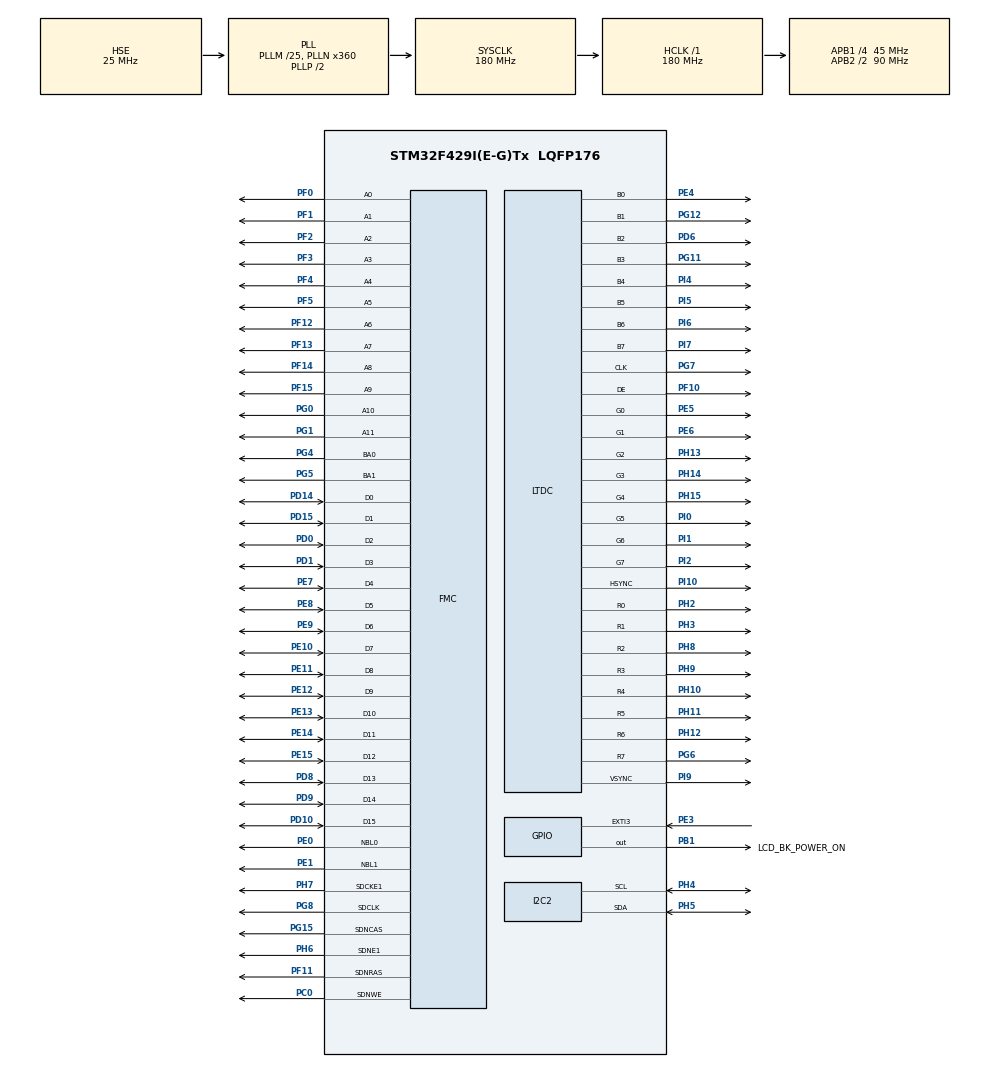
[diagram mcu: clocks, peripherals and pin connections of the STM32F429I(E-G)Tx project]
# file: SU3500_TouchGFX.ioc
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FMC.CASLatency1=FMC_SDRAM_CAS_LATENCY_3
FMC.ExitSelfRefreshDelay1=7
FMC.LoadToActiveDelay1=2
FMC.RCDDelay1=2
FMC.RPDelay1=2
FMC.ReadPipeDelay1=FMC_SDRAM_RPIPE_DELAY_1
FMC.RowCycleDelay1=6
FMC.SDClockPeriod1=FMC_SDRAM_CLOCK_PERIOD_2
FMC.SelfRefreshTime1=4
FMC.WriteRecoveryTime1=3
LTDC.ActiveW=800
LTDC.Alpha_L0=255
LTDC.DEPolarity=LTDC_DEPOLARITY_AL
LTDC.FBStartAdress_L0=0xD0000000
LTDC.HBP=88
LTDC.HFP=40
LTDC.HSync=48
LTDC.ImageHeight_L0=480
LTDC.ImageWidth_L0=800
LTDC.Layers=0
LTDC.PixelFormat_L0=LTDC_PIXEL_FORMAT_RGB888
LTDC.VBP=32
LTDC.VFP=13
LTDC.VSync=3
LTDC.WindowX1_L0=800
LTDC.WindowY1_L0=480
Mcu.Family=STM32F4
Mcu.Name=STM32F429I(E-G)Tx
Mcu.Package=LQFP176
NVIC.EXTI3_IRQn=true\:0\:0\:false\:false\:true\:true\:true\:true
NVIC.I2C2_ER_IRQn=true\:0\:0\:false\:false\:true\:true\:true\:true
NVIC.I2C2_EV_IRQn=true\:0\:0\:false\:false\:true\:true\:true\:true
NVIC.LTDC_IRQn=true\:0\:0\:false\:false\:true\:true\:true\:true
NVIC.PriorityGroup=NVIC_PRIORITYGROUP_4
PA13.Mode=Serial_Wire
PA13.Signal=SYS_JTMS-SWDIO
PA14.Mode=Serial_Wire
PA14.Signal=SYS_JTCK-SWCLK
PB1.GPIO_Label=LCD_BK_POWER_ON
PB1.PinState=GPIO_PIN_SET
PB1.Signal=GPIO_Output
PC0.Signal=FMC_SDNWE
PD0.Signal=FMC_D2_DA2
PD1.Signal=FMC_D3_DA3
PD10.Signal=FMC_D15_DA15
PD14.Signal=FMC_D0_DA0
PD15.Signal=FMC_D1_DA1
PD6.Mode=RGB888
PD6.Signal=LTDC_B2
PD8.Signal=FMC_D13_DA13
PD9.Signal=FMC_D14_DA14
PE0.Signal=FMC_NBL0
PE1.Signal=FMC_NBL1
PE10.Signal=FMC_D7_DA7
PE11.Signal=FMC_D8_DA8
PE12.Signal=FMC_D9_DA9
PE13.Signal=FMC_D10_DA10
PE14.Signal=FMC_D11_DA11
PE15.Signal=FMC_D12_DA12
PE3.GPIO_ModeDefaultEXTI=GPIO_MODE_IT_FALLING
PE3.GPIO_PuPd=GPIO_PULLUP
PE3.Signal=GPXTI3
PE4.GPIO_Speed=GPIO_SPEED_FREQ_VERY_HIGH
PE4.Mode=RGB888
PE4.Signal=LTDC_B0
PE5.Mode=RGB888
PE5.Signal=LTDC_G0
PE6.Mode=RGB888
PE6.Signal=LTDC_G1
PE7.Signal=FMC_D4_DA4
PE8.Signal=FMC_D5_DA5
PE9.Signal=FMC_D6_DA6
PF0.Signal=FMC_A0
PF1.Signal=FMC_A1
PF10.GPIO_Speed=GPIO_SPEED_FREQ_VERY_HIGH
PF10.Mode=RGB888
PF10.Signal=LTDC_DE
PF11.Signal=FMC_SDNRAS
PF12.Signal=FMC_A6
PF13.Signal=FMC_A7
PF14.Signal=FMC_A8
PF15.Signal=FMC_A9
PF2.Signal=FMC_A2
PF3.Signal=FMC_A3
PF4.Signal=FMC_A4
PF5.Signal=FMC_A5
PG0.Signal=FMC_A10
PG1.Signal=FMC_A11
PG11.GPIO_Speed=GPIO_SPEED_FREQ_VERY_HIGH
PG11.Mode=RGB888
PG11.Signal=LTDC_B3
PG12.Mode=RGB888
PG12.Signal=LTDC_B1
PG15.Signal=FMC_SDNCAS
PG4.Signal=FMC_A14_BA0
PG5.Signal=FMC_A15_BA1
PG6.GPIO_Speed=GPIO_SPEED_FREQ_VERY_HIGH
PG6.Mode=RGB888
PG6.Signal=LTDC_R7
PG7.GPIO_Speed=GPIO_SPEED_FREQ_VERY_HIGH
PG7.Mode=RGB888
PG7.Signal=LTDC_CLK
PG8.Signal=FMC_SDCLK
PH0/OSC_IN.Mode=HSE-External-Oscillator
PH0/OSC_IN.Signal=RCC_OSC_IN
PH1/OSC_OUT.Mode=HSE-External-Oscillator
PH1/OSC_OUT.Signal=RCC_OSC_OUT
PH10.GPIO_Speed=GPIO_SPEED_FREQ_VERY_HIGH
PH10.Mode=RGB888
PH10.Signal=LTDC_R4
PH11.GPIO_Speed=GPIO_SPEED_FREQ_VERY_HIGH
PH11.Mode=RGB888
PH11.Signal=LTDC_R5
PH12.GPIO_Speed=GPIO_SPEED_FREQ_VERY_HIGH
PH12.Mode=RGB888
PH12.Signal=LTDC_R6
PH13.GPIO_Speed=GPIO_SPEED_FREQ_VERY_HIGH
PH13.Mode=RGB888
PH13.Signal=LTDC_G2
PH14.GPIO_Speed=GPIO_SPEED_FREQ_VERY_HIGH
PH14.Mode=RGB888
PH14.Signal=LTDC_G3
PH15.GPIO_Speed=GPIO_SPEED_FREQ_VERY_HIGH
PH15.Mode=RGB888
PH15.Signal=LTDC_G4
PH2.Mode=RGB888
PH2.Signal=LTDC_R0
PH3.Mode=RGB888
PH3.Signal=LTDC_R1
PH4.Mode=I2C
PH4.Signal=I2C2_SCL
PH5.Mode=I2C
PH5.Signal=I2C2_SDA
PH6.Mode=SdramChipSelect2_1
PH6.Signal=FMC_SDNE1
PH7.Mode=SdramChipSelect2_1
PH7.Signal=FMC_SDCKE1
PH8.Mode=RGB888
PH8.Signal=LTDC_R2
PH9.GPIO_Speed=GPIO_SPEED_FREQ_VERY_HIGH
PH9.Mode=RGB888
PH9.Signal=LTDC_R3
PI0.GPIO_Speed=GPIO_SPEED_FREQ_VERY_HIGH
PI0.Mode=RGB888
PI0.Signal=LTDC_G5
PI1.GPIO_Speed=GPIO_SPEED_FREQ_VERY_HIGH
PI1.Mode=RGB888
PI1.Signal=LTDC_G6
PI10.GPIO_Speed=GPIO_SPEED_FREQ_VERY_HIGH
PI10.Mode=RGB888
PI10.Signal=LTDC_HSYNC
PI2.GPIO_Speed=GPIO_SPEED_FREQ_VERY_HIGH
PI2.Mode=RGB888
PI2.Signal=LTDC_G7
PI4.GPIO_Speed=GPIO_SPEED_FREQ_VERY_HIGH
PI4.Mode=RGB888
PI4.Signal=LTDC_B4
PI5.GPIO_Speed=GPIO_SPEED_FREQ_VERY_HIGH
PI5.Mode=RGB888
PI5.Signal=LTDC_B5
PI6.GPIO_Speed=GPIO_SPEED_FREQ_VERY_HIGH
PI6.Mode=RGB888
PI6.Signal=LTDC_B6
PI7.GPIO_Speed=GPIO_SPEED_FREQ_VERY_HIGH
PI7.Mode=RGB888
PI7.Signal=LTDC_B7
PI9.GPIO_Speed=GPIO_SPEED_FREQ_VERY_HIGH
PI9.Mode=RGB888
PI9.Signal=LTDC_VSYNC
ProjectManager.HeapSize=0x200
ProjectManager.StackSize=0x400
ProjectManager.TargetToolchain=STM32CubeIDE
RCC.48MHZClocksFreq_Value=90000000
RCC.AHBFreq_Value=180000000
RCC.APB1CLKDivider=RCC_HCLK_DIV4
RCC.APB1Freq_Value=45000000
RCC.APB1TimFreq_Value=90000000
RCC.APB2CLKDivider=RCC_HCLK_DIV2
RCC.APB2Freq_Value=90000000
RCC.APB2TimFreq_Value=180000000
RCC.CortexFreq_Value=180000000
RCC.HCLKFreq_Value=180000000
RCC.HSE_VALUE=25000000
RCC.HSI_VALUE=16000000
RCC.LSE_VALUE=32768
RCC.PLLM=25
RCC.PLLN=360
RCC.PLLSAIN=192
RCC.PLLSAIR=4
RCC.PLLSourceVirtual=RCC_PLLSOURCE_HSE
RCC.SYSCLKFreq_VALUE=180000000
RCC.SYSCLKSource=RCC_SYSCLKSOURCE_PLLCLK
RCC.VCOOutputFreq_Value=360000000
SH.FMC_A0.0=FMC_A0,12b-sda1
SH.FMC_A1.0=FMC_A1,12b-sda1
SH.FMC_A10.0=FMC_A10,12b-sda1
SH.FMC_A11.0=FMC_A11,12b-sda1
SH.FMC_A14_BA0.0=FMC_BA0,FourSdramBanks1
SH.FMC_A15_BA1.0=FMC_BA1,FourSdramBanks1
SH.FMC_A2.0=FMC_A2,12b-sda1
SH.FMC_A3.0=FMC_A3,12b-sda1
SH.FMC_A4.0=FMC_A4,12b-sda1
SH.FMC_A5.0=FMC_A5,12b-sda1
SH.FMC_A6.0=FMC_A6,12b-sda1
SH.FMC_A7.0=FMC_A7,12b-sda1
SH.FMC_A8.0=FMC_A8,12b-sda1
SH.FMC_A9.0=FMC_A9,12b-sda1
SH.FMC_D0_DA0.0=FMC_D0,sd-16b-d1
SH.FMC_D10_DA10.0=FMC_D10,sd-16b-d1
SH.FMC_D11_DA11.0=FMC_D11,sd-16b-d1
SH.FMC_D12_DA12.0=FMC_D12,sd-16b-d1
SH.FMC_D13_DA13.0=FMC_D13,sd-16b-d1
SH.FMC_D14_DA14.0=FMC_D14,sd-16b-d1
SH.FMC_D15_DA15.0=FMC_D15,sd-16b-d1
SH.FMC_D1_DA1.0=FMC_D1,sd-16b-d1
SH.FMC_D2_DA2.0=FMC_D2,sd-16b-d1
SH.FMC_D3_DA3.0=FMC_D3,sd-16b-d1
SH.FMC_D4_DA4.0=FMC_D4,sd-16b-d1
SH.FMC_D5_DA5.0=FMC_D5,sd-16b-d1
SH.FMC_D6_DA6.0=FMC_D6,sd-16b-d1
SH.FMC_D7_DA7.0=FMC_D7,sd-16b-d1
SH.FMC_D8_DA8.0=FMC_D8,sd-16b-d1
SH.FMC_D9_DA9.0=FMC_D9,sd-16b-d1
SH.FMC_NBL0.0=FMC_NBL0,Sd2ByteEnable1
SH.FMC_NBL1.0=FMC_NBL1,Sd2ByteEnable1
SH.FMC_SDCLK.0=FMC_SDCLK,12b-sda1
SH.FMC_SDNCAS.0=FMC_SDNCAS,12b-sda1
SH.FMC_SDNRAS.0=FMC_SDNRAS,12b-sda1
SH.FMC_SDNWE.0=FMC_SDNWE,12b-sda1
STMicroelectronics.X-CUBE-TOUCHGFX.4.26.0.ApplicationCcGraphicsJjApplication=TouchGFXOoGenerator
STMicroelectronics.X-CUBE-TOUCHGFX.4.26.0.tgfx_custom_height=480
STMicroelectronics.X-CUBE-TOUCHGFX.4.26.0.tgfx_display_interface=disp_ltdc
STMicroelectronics.X-CUBE-TOUCHGFX.4.26.0.tgfx_location=Allocate
STMicroelectronics.X-CUBE-TOUCHGFX.4.26.0.tgfx_pixel_format=RGB888\:24
STMicroelectronics.X-CUBE-TOUCHGFX.4.26.0.tgfx_vsync=vsync_ltdc
STMicroelectronics.X-CUBE-TOUCHGFX.4.26.0_IsPackSelfContextualization=true
VP_CRC_VS_CRC.Mode=CRC_Activate
VP_STMicroelectronics.X-CUBE-TOUCHGFX_VS_GraphicsJjApplication_4.26.0.Mode=GraphicsJjApplication
board=custom

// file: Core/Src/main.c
/* USER CODE BEGIN Header */
/**
  ******************************************************************************
  * @file           : main.c
  * @brief          : Main program body
  ******************************************************************************
  * @attention
  *
  * Copyright (c) 2025 STMicroelectronics.
  * All rights reserved.
  *
  * This software is licensed under terms that can be found in the LICENSE file
  * in the root directory of this software component.
  * If no LICENSE file comes with this software, it is provided AS-IS.
  *
  ******************************************************************************
  */
/* USER CODE END Header */
#include "main.h"
#include "crc.h"
#include "i2c.h"
#include "ltdc.h"
#include "gpio.h"
#include "fmc.h"
#include "app_touchgfx.h"

/* USER CODE BEGIN Includes */
#include "../../Drivers/CustomDriver/ak4183.h"
/* USER CODE END Includes */

/* USER CODE BEGIN PV */
//__attribute__((section(".TouchGFX_Framebuffer"))) __attribute__((aligned(32))) static uint32_t framebuffer[288000]; // RGB888

#define REFRESH_COUNT        1386
#define SDRAM_TIMEOUT                            ((uint32_t)0xFFFF)
#define SDRAM_MODEREG_BURST_LENGTH_1             ((uint16_t)0x0000)
#define SDRAM_MODEREG_BURST_LENGTH_2             ((uint16_t)0x0001)
#define SDRAM_MODEREG_BURST_LENGTH_4             ((uint16_t)0x0002)
#define SDRAM_MODEREG_BURST_LENGTH_8             ((uint16_t)0x0004)
#define SDRAM_MODEREG_BURST_TYPE_SEQUENTIAL      ((uint16_t)0x0000)
#define SDRAM_MODEREG_BURST_TYPE_INTERLEAVED     ((uint16_t)0x0008)
#define SDRAM_MODEREG_CAS_LATENCY_2              ((uint16_t)0x0020)
#define SDRAM_MODEREG_CAS_LATENCY_3              ((uint16_t)0x0030)
#define SDRAM_MODEREG_OPERATING_MODE_STANDARD    ((uint16_t)0x0000)
#define SDRAM_MODEREG_WRITEBURST_MODE_PROGRAMMED ((uint16_t)0x0000)
#define SDRAM_MODEREG_WRITEBURST_MODE_SINGLE     ((uint16_t)0x0200)

static FMC_SDRAM_CommandTypeDef Command;

//extern AK4183_Handle_t ak4183_handle;  // STM32TouchController.cpp에서 정의됨
AK4183_Handle_t *g_ak4183_handle = NULL;

/* USER CODE END PV */

void SystemClock_Config(void);
/* USER CODE BEGIN PFP */
static void SDRAM_Initialization_Sequence(SDRAM_HandleTypeDef *hsdram);

// 터치 테스트 함수 (디버그용)
static void Test_TouchController(void);
/* USER CODE END PFP */

/* USER CODE BEGIN 0 */
/**
 * @brief 터치 감지 콜백 함수
 * @param data 터치 데이터
 */
void Touch_Detected_Callback(AK4183_TouchData_t *data)
{
    // 터치 감지 시 처리
    // 예: LED 토글
    HAL_GPIO_TogglePin(GPIOB, GPIO_PIN_1);

    // 터치 좌표 정보 출력 (디버그용)
    #ifdef AK4183_DEBUG
    AK4183_PrintTouchData(data);
    #endif
}

/**
 * @brief 터치 해제 콜백 함수
 */
void Touch_Released_Callback(void)
{
    // 터치 해제 시 처리
    // 예: LED 끄기
    HAL_GPIO_WritePin(GPIOB, GPIO_PIN_1, GPIO_PIN_RESET);
}

/**
 * @brief EXTI 인터럽트 콜백 함수 (HAL에서 호출)
 * @param GPIO_Pin 인터럽트가 발생한 GPIO 핀
 * @note 이 함수는 HAL_GPIO_EXTI_IRQHandler에서 자동으로 호출됨
 */
void HAL_GPIO_EXTI_Callback(uint16_t GPIO_Pin)
{
    if (GPIO_Pin == GPIO_PIN_3) {  // PE3 핀 (PENIRQN)
        if (g_ak4183_handle != NULL) {
            // AK4183 인터럽트 핸들러 호출
            AK4183_IRQHandler(g_ak4183_handle);
        }
    }
}

/**
 * @brief 터치 컨트롤러 초기화
 * @return 0: 성공, 1: 실패
 */
static int Init_TouchController(void)
{
    // 전역 핸들 얻기
    g_ak4183_handle = AK4183_GetHandle();

    // AK4183 초기화
    if (AK4183_Init(g_ak4183_handle, &hi2c2) != AK4183_OK) {
        return 1;  // 초기화 실패
    }

    // 콜백 함수 등록
    AK4183_RegisterTouchDetectedCallback(g_ak4183_handle, Touch_Detected_Callback);
    AK4183_RegisterTouchReleasedCallback(g_ak4183_handle, Touch_Released_Callback);

    return 0;  // 성공
}

/**
 * @brief 터치 컨트롤러 테스트 함수 (폴링 방식)
 * @note 디버그 목적으로 터치 동작을 확인
 */
static void Test_TouchController_Polling(void)
{
    AK4183_TouchData_t touch_data;

    // 터치 컨트롤러 초기화
    if (Init_TouchController() == 0) {
        // LED 켜기 (초기화 성공)
        HAL_GPIO_WritePin(GPIOB, GPIO_PIN_1, GPIO_PIN_SET);

        // 5초간 터치 테스트
        uint32_t start_time = HAL_GetTick();
        while ((HAL_GetTick() - start_time) < 5000) {
            // 터치 데이터 읽기
            if (AK4183_ReadTouch(g_ak4183_handle, &touch_data) == AK4183_OK) {
                if (touch_data.state == AK4183_TOUCH_PRESSED) {
                    // 터치됨 - LED 토글
                    HAL_GPIO_TogglePin(GPIOB, GPIO_PIN_1);

                    // 디버그 출력
                    #ifdef AK4183_DEBUG
                    AK4183_PrintTouchData(&touch_data);
                    #endif
                }
            }
            HAL_Delay(50);  // 50ms 주기로 확인
        }

        // LED 끄기
        HAL_GPIO_WritePin(GPIOB, GPIO_PIN_1, GPIO_PIN_RESET);
    }
}
/* USER CODE END 0 */

int main(void)
{

  /* MCU Configuration--------------------------------------------------------*/

  /* Reset of all peripherals, Initializes the Flash interface and the Systick. */
  HAL_Init();

  /* Configure the system clock */
  SystemClock_Config();

  /* Initialize all configured peripherals */
  MX_GPIO_Init();
  MX_CRC_Init();
  MX_FMC_Init();
  MX_LTDC_Init();
  MX_I2C2_Init();
  MX_TouchGFX_Init();
  /* USER CODE BEGIN 2 */
  SDRAM_Initialization_Sequence(&hsdram1);

  // 터치 컨트롤러 초기화
  if (Init_TouchController() != 0) {
      // 초기화 실패 시 LED로 에러 표시
      while(1) {
          HAL_GPIO_TogglePin(GPIOB, GPIO_PIN_1);
          HAL_Delay(200);
      }
  }

  // 터치 컨트롤러 테스트 (디버그용 - 필요시 주석 해제)
  // #define TOUCH_DEBUG_TEST
  #ifdef TOUCH_DEBUG_TEST
  Test_TouchController_Polling();
  #endif

  /* USER CODE END 2 */

  /* Infinite loop */
  while (1)
  {

  MX_TouchGFX_Process();
  }
}

void SystemClock_Config(void)
{
  RCC_OscInitTypeDef RCC_OscInitStruct = {0};
  RCC_ClkInitTypeDef RCC_ClkInitStruct = {0};

  /** Configure the main internal regulator output voltage
  */
  __HAL_RCC_PWR_CLK_ENABLE();
  __HAL_PWR_VOLTAGESCALING_CONFIG(PWR_REGULATOR_VOLTAGE_SCALE1);

  /** Initializes the RCC Oscillators according to the specified parameters
  * in the RCC_OscInitTypeDef structure.
  */
  RCC_OscInitStruct.OscillatorType = RCC_OSCILLATORTYPE_HSE;
  RCC_OscInitStruct.HSEState = RCC_HSE_ON;
  RCC_OscInitStruct.PLL.PLLState = RCC_PLL_ON;
  RCC_OscInitStruct.PLL.PLLSource = RCC_PLLSOURCE_HSE;
  RCC_OscInitStruct.PLL.PLLM = 25;
  RCC_OscInitStruct.PLL.PLLN = 360;
  RCC_OscInitStruct.PLL.PLLP = RCC_PLLP_DIV2;
  RCC_OscInitStruct.PLL.PLLQ = 4;
  if (HAL_RCC_OscConfig(&RCC_OscInitStruct) != HAL_OK)
  {
    Error_Handler();
  }

  /** Activate the Over-Drive mode
  */
  if (HAL_PWREx_EnableOverDrive() != HAL_OK)
  {
    Error_Handler();
  }

  /** Initializes the CPU, AHB and APB buses clocks
  */
  RCC_ClkInitStruct.ClockType = RCC_CLOCKTYPE_HCLK|RCC_CLOCKTYPE_SYSCLK
                              |RCC_CLOCKTYPE_PCLK1|RCC_CLOCKTYPE_PCLK2;
  RCC_ClkInitStruct.SYSCLKSource = RCC_SYSCLKSOURCE_PLLCLK;
  RCC_ClkInitStruct.AHBCLKDivider = RCC_SYSCLK_DIV1;
  RCC_ClkInitStruct.APB1CLKDivider = RCC_HCLK_DIV4;
  RCC_ClkInitStruct.APB2CLKDivider = RCC_HCLK_DIV2;

  if (HAL_RCC_ClockConfig(&RCC_ClkInitStruct, FLASH_LATENCY_5) != HAL_OK)
  {
    Error_Handler();
  }
}

/* USER CODE BEGIN 4 */
void SDRAM_Initialization_Sequence(SDRAM_HandleTypeDef *hsdram)
{
  __IO uint32_t tmpmrd = 0;

  /* Step 1: Clock Configuration Enable */
  Command.CommandMode = FMC_SDRAM_CMD_CLK_ENABLE;
  Command.CommandTarget = FMC_SDRAM_CMD_TARGET_BANK2;
  Command.AutoRefreshNumber = 1;
  Command.ModeRegisterDefinition = 0;
  HAL_SDRAM_SendCommand(hsdram, &Command, SDRAM_TIMEOUT);
  HAL_Delay(1); // 1ms

  /* Step 2: PALL (Precharge All) */
  Command.CommandMode = FMC_SDRAM_CMD_PALL;
  Command.CommandTarget = FMC_SDRAM_CMD_TARGET_BANK2;
  Command.AutoRefreshNumber = 1;
  Command.ModeRegisterDefinition = 0;
  HAL_SDRAM_SendCommand(hsdram, &Command, SDRAM_TIMEOUT);

  /* Step 3: Auto-refresh */
  Command.CommandMode = FMC_SDRAM_CMD_AUTOREFRESH_MODE;
  Command.CommandTarget = FMC_SDRAM_CMD_TARGET_BANK2;
  Command.AutoRefreshNumber = 8;
  Command.ModeRegisterDefinition = 0;
  HAL_SDRAM_SendCommand(hsdram, &Command, SDRAM_TIMEOUT);

  /* Step 4: Load Mode Register */
  tmpmrd = (uint32_t)SDRAM_MODEREG_BURST_LENGTH_2   |
                     SDRAM_MODEREG_BURST_TYPE_SEQUENTIAL |
                     SDRAM_MODEREG_CAS_LATENCY_3         |
                     SDRAM_MODEREG_OPERATING_MODE_STANDARD |
                     SDRAM_MODEREG_WRITEBURST_MODE_SINGLE;
  Command.CommandMode = FMC_SDRAM_CMD_LOAD_MODE;
  Command.CommandTarget = FMC_SDRAM_CMD_TARGET_BANK2;
  Command.AutoRefreshNumber = 1;
  Command.ModeRegisterDefinition = tmpmrd;
  HAL_SDRAM_SendCommand(hsdram, &Command, SDRAM_TIMEOUT);

  /* Step 5: Set a clock configuration enable command */
  HAL_SDRAM_ProgramRefreshRate(hsdram, REFRESH_COUNT);
}

/**
  * @brief 터치 컨트롤러 테스트 함수
  * @note 디버그 목적으로 터치 동작을 확인
  */
static void Test_TouchController(void)
{
    AK4183_Handle_t test_handle;
    AK4183_TouchData_t touch_data;

    // 터치 컨트롤러 초기화
    if (AK4183_Init(&test_handle, &hi2c2) == AK4183_OK) {
        // LED 켜기 (초기화 성공)
        HAL_GPIO_WritePin(GPIOB, GPIO_PIN_1, GPIO_PIN_SET);

        // 5초간 터치 테스트
        uint32_t start_time = HAL_GetTick();
        while ((HAL_GetTick() - start_time) < 5000) {
            // 터치 데이터 읽기
            if (AK4183_ReadTouch(&test_handle, &touch_data) == AK4183_OK) {
                if (touch_data.state == AK4183_TOUCH_PRESSED) {
                    // 터치됨 - LED 토글
                    HAL_GPIO_TogglePin(GPIOB, GPIO_PIN_1);

                    // 디버그 출력 (UART나 SWO 사용 시)
                    #ifdef USE_DEBUG_UART
                    printf("Touch: X=%d, Y=%d, Pressure=%d\n",
                           touch_data.x, touch_data.y, touch_data.pressure);
                    #endif
                }
            }
            HAL_Delay(50);  // 50ms 주기로 확인
        }
    }
}
/* USER CODE END 4 */

void Error_Handler(void)
{
  __disable_irq();
  while (1)
  {
  }
}
